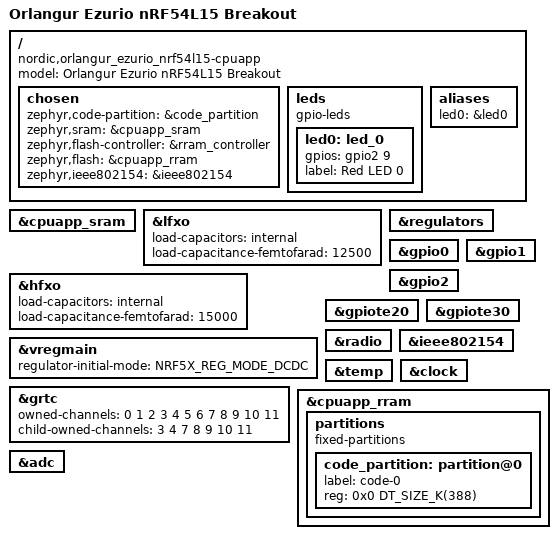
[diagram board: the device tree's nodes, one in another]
/*
 * Copyright (c) 2024 Nordic Semiconductor ASA
 *
 * SPDX-License-Identifier: Apache-2.0
 */

/dts-v1/;

#include <nordic/nrf54l15_cpuapp.dtsi>

/ {
	compatible = "nordic,orlangur_ezurio_nrf54l15-cpuapp";
	model = "Orlangur Ezurio nRF54L15 Breakout";

	chosen {
		zephyr,code-partition = &code_partition;
		zephyr,sram = &cpuapp_sram;
		zephyr,flash-controller = &rram_controller;
		zephyr,flash = &cpuapp_rram;
		zephyr,ieee802154 = &ieee802154;
	};

	leds {
		compatible = "gpio-leds";
		led0: led_0 {
			gpios = <&gpio2 9 GPIO_ACTIVE_HIGH>;
			label = "Red LED 0";
		};
	};

	aliases {
		led0 = &led0;
	};
};

&cpuapp_sram {
	status = "okay";
};

&lfxo {
	load-capacitors = "internal";
	load-capacitance-femtofarad = <12500>;
};

&hfxo {
	load-capacitors = "internal";
	load-capacitance-femtofarad = <15000>;
};

&regulators {
	status = "okay";
};

&vregmain {
	status = "okay";
	regulator-initial-mode = <NRF5X_REG_MODE_DCDC>;
};

&grtc {
	owned-channels = <0 1 2 3 4 5 6 7 8 9 10 11>;
	/* Channels 7-11 reserved for Zero Latency IRQs, 3-4 for FLPR */
	child-owned-channels = <3 4 7 8 9 10 11>;
	status = "okay";
};

&gpio0 {
	status = "okay";
};

&gpio1 {
	status = "okay";
};

&gpio2 {
	status = "okay";
};

&gpiote20 {
	status = "okay";
};

&gpiote30 {
	status = "okay";
};

&radio {
	status = "okay";
};

&ieee802154 {
	status = "okay";
};

&temp {
	status = "okay";
};

&clock {
	status = "okay";
};

&cpuapp_rram {
	status = "okay";
	partitions {
		compatible = "fixed-partitions";
		#address-cells = <1>;
		#size-cells = <1>;
		code_partition: partition@0 {
			label = "code-0";
			reg = <0x0 DT_SIZE_K(388)>;
		};
	};
};

&adc {
	status = "okay";
};
